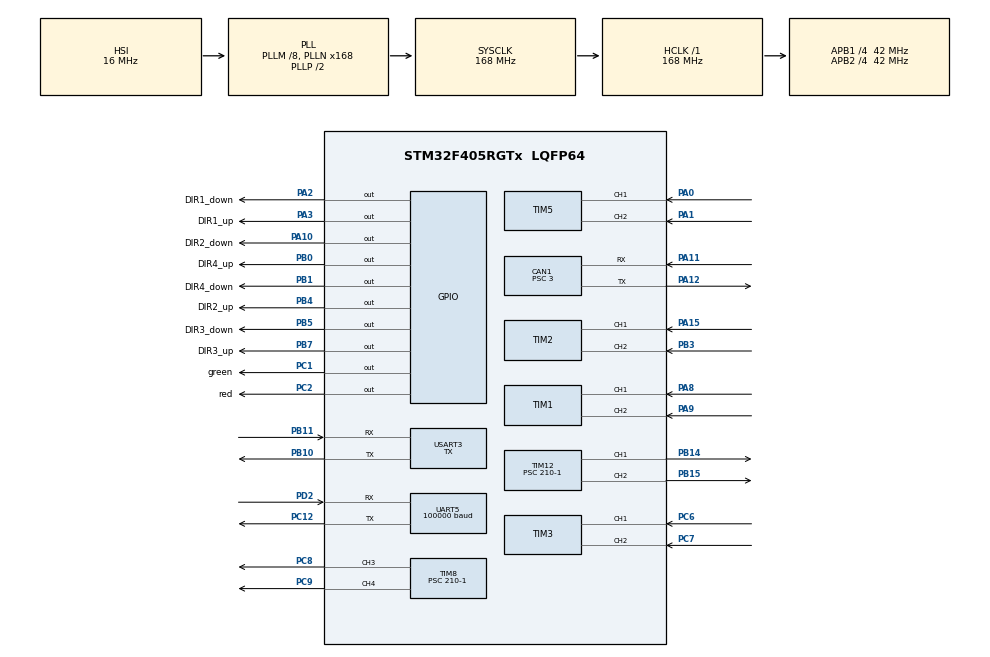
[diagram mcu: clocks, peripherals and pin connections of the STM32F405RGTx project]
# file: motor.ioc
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CAN1.ABOM=ENABLE
CAN1.BS1=CAN_BS1_9TQ
CAN1.BS2=CAN_BS2_4TQ
CAN1.CalculateBaudRate=1000000
CAN1.CalculateTimeBit=1000
CAN1.CalculateTimeQuantum=71.42857142857143
CAN1.Prescaler=3
Dma.Request0=UART5_RX
Dma.Request1=USART3_TX
Dma.UART5_RX.0.Direction=DMA_PERIPH_TO_MEMORY
Dma.UART5_RX.0.FIFOMode=DMA_FIFOMODE_DISABLE
Dma.UART5_RX.0.Instance=DMA1_Stream0
Dma.UART5_RX.0.MemDataAlignment=DMA_MDATAALIGN_BYTE
Dma.UART5_RX.0.MemInc=DMA_MINC_ENABLE
Dma.UART5_RX.0.Mode=DMA_NORMAL
Dma.UART5_RX.0.PeriphDataAlignment=DMA_PDATAALIGN_BYTE
Dma.UART5_RX.0.PeriphInc=DMA_PINC_DISABLE
Dma.UART5_RX.0.Priority=DMA_PRIORITY_LOW
Dma.USART3_TX.1.Direction=DMA_MEMORY_TO_PERIPH
Dma.USART3_TX.1.FIFOMode=DMA_FIFOMODE_DISABLE
Dma.USART3_TX.1.Instance=DMA1_Stream3
Dma.USART3_TX.1.MemDataAlignment=DMA_MDATAALIGN_BYTE
Dma.USART3_TX.1.MemInc=DMA_MINC_ENABLE
Dma.USART3_TX.1.Mode=DMA_NORMAL
Dma.USART3_TX.1.PeriphDataAlignment=DMA_PDATAALIGN_BYTE
Dma.USART3_TX.1.PeriphInc=DMA_PINC_DISABLE
Dma.USART3_TX.1.Priority=DMA_PRIORITY_LOW
Mcu.Family=STM32F4
Mcu.Name=STM32F405RGTx
Mcu.Package=LQFP64
NVIC.DMA1_Stream0_IRQn=true\:0\:0\:false\:false\:true\:false\:true\:true
NVIC.DMA1_Stream3_IRQn=true\:0\:0\:false\:false\:true\:false\:true\:true
NVIC.PVD_IRQn=true\:0\:0\:false\:false\:true\:true\:true\:true
NVIC.PriorityGroup=NVIC_PRIORITYGROUP_2
NVIC.TIM1_UP_TIM10_IRQn=true\:0\:2\:false\:false\:true\:true\:true\:true
NVIC.TIM7_IRQn=true\:0\:1\:true\:false\:true\:true\:true\:true
NVIC.TIM8_TRG_COM_TIM14_IRQn=true\:0\:0\:false\:false\:true\:true\:true\:true
NVIC.UART5_IRQn=true\:0\:0\:false\:false\:true\:true\:true\:true
NVIC.USART3_IRQn=true\:0\:0\:false\:false\:true\:true\:true\:true
PA0-WKUP.Signal=S_TIM5_CH1
PA1.Signal=S_TIM5_CH2
PA10.GPIO_Label=DIR2_down
PA10.Signal=GPIO_Output
PA11.Mode=CAN_Activate
PA11.Signal=CAN1_RX
PA12.Mode=CAN_Activate
PA12.Signal=CAN1_TX
PA13.Mode=Serial_Wire
PA13.Signal=SYS_JTMS-SWDIO
PA14.Mode=Serial_Wire
PA14.Signal=SYS_JTCK-SWCLK
PA15.Signal=S_TIM2_CH1_ETR
PA2.GPIO_Label=DIR1_down
PA2.Signal=GPIO_Output
PA3.GPIO_Label=DIR1_up
PA3.Signal=GPIO_Output
PA8.Signal=S_TIM1_CH1
PA9.Signal=S_TIM1_CH2
PB0.GPIO_Label=DIR4_up
PB0.Signal=GPIO_Output
PB1.GPIO_Label=DIR4_down
PB1.Signal=GPIO_Output
PB10.Mode=Asynchronous
PB10.Signal=USART3_TX
PB11.Mode=Asynchronous
PB11.Signal=USART3_RX
PB14.Signal=S_TIM12_CH1
PB15.Signal=S_TIM12_CH2
PB3.Signal=S_TIM2_CH2
PB4.GPIO_Label=DIR2_up
PB4.Signal=GPIO_Output
PB5.GPIO_Label=DIR3_down
PB5.Signal=GPIO_Output
PB7.GPIO_Label=DIR3_up
PB7.Signal=GPIO_Output
PC1.GPIO_Label=green
PC1.PinState=GPIO_PIN_SET
PC1.Signal=GPIO_Output
PC12.Mode=Asynchronous
PC12.Signal=UART5_TX
PC2.GPIO_Label=red
PC2.PinState=GPIO_PIN_SET
PC2.Signal=GPIO_Output
PC6.Signal=S_TIM3_CH1
PC7.Signal=S_TIM3_CH2
PC8.Signal=S_TIM8_CH3
PC9.Signal=S_TIM8_CH4
PD2.Mode=Asynchronous
PD2.Signal=UART5_RX
PH0-OSC_IN.Mode=HSE-External-Oscillator
PH0-OSC_IN.Signal=RCC_OSC_IN
PH1-OSC_OUT.Mode=HSE-External-Oscillator
PH1-OSC_OUT.Signal=RCC_OSC_OUT
ProjectManager.HeapSize=0x200
ProjectManager.StackSize=0x400
ProjectManager.TargetToolchain=MDK-ARM V5.32
RCC.48MHZClocksFreq_Value=84000000
RCC.AHBFreq_Value=168000000
RCC.APB1CLKDivider=RCC_HCLK_DIV4
RCC.APB1Freq_Value=42000000
RCC.APB1TimFreq_Value=84000000
RCC.APB2CLKDivider=RCC_HCLK_DIV4
RCC.APB2Freq_Value=42000000
RCC.APB2TimFreq_Value=84000000
RCC.CortexFreq_Value=168000000
RCC.HCLKFreq_Value=168000000
RCC.HSE_VALUE=8000000
RCC.HSI_VALUE=16000000
RCC.LSE_VALUE=32768
RCC.PLLM=8
RCC.PLLN=168
RCC.SYSCLKFreq_VALUE=168000000
RCC.SYSCLKSource=RCC_SYSCLKSOURCE_PLLCLK
RCC.VCOOutputFreq_Value=336000000
SH.S_TIM12_CH1.0=TIM12_CH1,PWM Generation1 CH1
SH.S_TIM12_CH2.0=TIM12_CH2,PWM Generation2 CH2
SH.S_TIM1_CH1.0=TIM1_CH1,Encoder_Interface
SH.S_TIM1_CH2.0=TIM1_CH2,Encoder_Interface
SH.S_TIM2_CH1_ETR.0=TIM2_CH1,Encoder_Interface
SH.S_TIM2_CH2.0=TIM2_CH2,Encoder_Interface
SH.S_TIM3_CH1.0=TIM3_CH1,Encoder_Interface
SH.S_TIM3_CH2.0=TIM3_CH2,Encoder_Interface
SH.S_TIM5_CH1.0=TIM5_CH1,Encoder_Interface
SH.S_TIM5_CH2.0=TIM5_CH2,Encoder_Interface
SH.S_TIM8_CH3.0=TIM8_CH3,PWM Generation3 CH3
SH.S_TIM8_CH4.0=TIM8_CH4,PWM Generation4 CH4
TIM1.EncoderMode=TIM_ENCODERMODE_TI12
TIM10.Period=250-1
TIM10.Prescaler=8400-1
TIM12.Channel-PWM\ Generation1\ CH1=TIM_CHANNEL_1
TIM12.Channel-PWM\ Generation2\ CH2=TIM_CHANNEL_2
TIM12.Period=100-1
TIM12.Prescaler=210-1
TIM14.Period=20000-1
TIM14.Prescaler=4200-1
TIM2.EncoderMode=TIM_ENCODERMODE_TI12
TIM3.EncoderMode=TIM_ENCODERMODE_TI12
TIM5.EncoderMode=TIM_ENCODERMODE_TI12
TIM7.Period=100-1
TIM7.Prescaler=4200-1
TIM8.Channel-PWM\ Generation3\ CH3=TIM_CHANNEL_3
TIM8.Channel-PWM\ Generation4\ CH4=TIM_CHANNEL_4
TIM8.Period=100-1
TIM8.Prescaler=210-1
UART5.BaudRate=100000
UART5.Mode=MODE_RX
UART5.Parity=PARITY_EVEN
UART5.VirtualMode=Asynchronous
UART5.WordLength=WORDLENGTH_9B
USART3.Mode=MODE_TX
USART3.VirtualMode=VM_ASYNC
VP_TIM10_VS_ClockSourceINT.Mode=Enable_Timer
VP_TIM14_VS_ClockSourceINT.Mode=Enable_Timer
VP_TIM7_VS_ClockSourceINT.Mode=Enable_Timer
board=custom

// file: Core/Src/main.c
/* USER CODE BEGIN Header */
/**
  ******************************************************************************
  * @file           : main.c
  * @brief          : Main program body
  ******************************************************************************
  * @attention
  *
  * Copyright (c) 2022 STMicroelectronics.
  * All rights reserved.
  *
  * This software is licensed under terms that can be found in the LICENSE file
  * in the root directory of this software component.
  * If no LICENSE file comes with this software, it is provided AS-IS.
  *
  ******************************************************************************
  */
/* USER CODE END Header */
#include "main.h"
#include "can.h"
#include "dma.h"
#include "tim.h"
#include "usart.h"
#include "gpio.h"

/* USER CODE BEGIN Includes */
#include "main_init.h"
/* USER CODE END Includes */

void SystemClock_Config(void);

int main(void)
{

  /* MCU Configuration--------------------------------------------------------*/

  /* Reset of all peripherals, Initializes the Flash interface and the Systick. */
  HAL_Init();

  /* Configure the system clock */
  SystemClock_Config();

  /* Initialize all configured peripherals */
  MX_GPIO_Init();
  MX_TIM7_Init();
  MX_TIM1_Init();
  MX_TIM10_Init();
  MX_TIM3_Init();
  MX_TIM14_Init();
  MX_TIM2_Init();
  MX_TIM5_Init();
  MX_TIM8_Init();
  MX_DMA_Init();
  MX_TIM12_Init();
  MX_UART5_Init();
  MX_CAN1_Init();
  MX_USART3_UART_Init();
  /* USER CODE BEGIN 2 */
  user_init();
  /* USER CODE END 2 */

  /* Infinite loop */
  while (1)
  {

  }
}

void SystemClock_Config(void)
{
  RCC_OscInitTypeDef RCC_OscInitStruct = {0};
  RCC_ClkInitTypeDef RCC_ClkInitStruct = {0};

  /** Configure the main internal regulator output voltage
  */
  __HAL_RCC_PWR_CLK_ENABLE();
  __HAL_PWR_VOLTAGESCALING_CONFIG(PWR_REGULATOR_VOLTAGE_SCALE1);

  /** Initializes the RCC Oscillators according to the specified parameters
  * in the RCC_OscInitTypeDef structure.
  */
  RCC_OscInitStruct.OscillatorType = RCC_OSCILLATORTYPE_HSI;
  RCC_OscInitStruct.HSIState = RCC_HSI_ON;
  RCC_OscInitStruct.HSICalibrationValue = RCC_HSICALIBRATION_DEFAULT;
  RCC_OscInitStruct.PLL.PLLState = RCC_PLL_ON;
  RCC_OscInitStruct.PLL.PLLSource = RCC_PLLSOURCE_HSI;
  RCC_OscInitStruct.PLL.PLLM = 8;
  RCC_OscInitStruct.PLL.PLLN = 168;
  RCC_OscInitStruct.PLL.PLLP = RCC_PLLP_DIV2;
  RCC_OscInitStruct.PLL.PLLQ = 4;
  if (HAL_RCC_OscConfig(&RCC_OscInitStruct) != HAL_OK)
  {
    Error_Handler();
  }

  /** Initializes the CPU, AHB and APB buses clocks
  */
  RCC_ClkInitStruct.ClockType = RCC_CLOCKTYPE_HCLK|RCC_CLOCKTYPE_SYSCLK
                              |RCC_CLOCKTYPE_PCLK1|RCC_CLOCKTYPE_PCLK2;
  RCC_ClkInitStruct.SYSCLKSource = RCC_SYSCLKSOURCE_PLLCLK;
  RCC_ClkInitStruct.AHBCLKDivider = RCC_SYSCLK_DIV1;
  RCC_ClkInitStruct.APB1CLKDivider = RCC_HCLK_DIV4;
  RCC_ClkInitStruct.APB2CLKDivider = RCC_HCLK_DIV4;

  if (HAL_RCC_ClockConfig(&RCC_ClkInitStruct, FLASH_LATENCY_5) != HAL_OK)
  {
    Error_Handler();
  }
}

void Error_Handler(void)
{
  __disable_irq();
  while (1)
  {
  }
}
